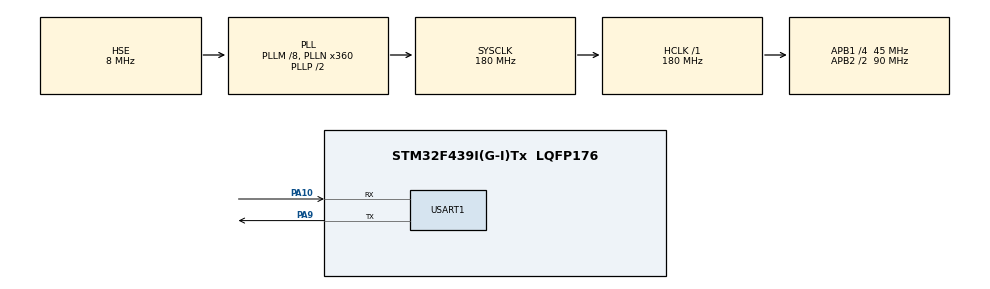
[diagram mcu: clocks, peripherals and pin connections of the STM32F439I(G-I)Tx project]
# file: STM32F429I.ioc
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Dma.Request0=USART1_TX
Dma.USART1_TX.0.Channel=DMA_CHANNEL_4
Dma.USART1_TX.0.Direction=DMA_MEMORY_TO_PERIPH
Dma.USART1_TX.0.FIFOMode=DMA_FIFOMODE_DISABLE
Dma.USART1_TX.0.Instance=DMA2_Stream7
Dma.USART1_TX.0.MemBurst=DMA_MBURST_SINGLE
Dma.USART1_TX.0.MemDataAlignment=DMA_MDATAALIGN_BYTE
Dma.USART1_TX.0.MemInc=DMA_MINC_ENABLE
Dma.USART1_TX.0.Mode=DMA_NORMAL
Dma.USART1_TX.0.PeriphBurst=DMA_PBURST_SINGLE
Dma.USART1_TX.0.PeriphDataAlignment=DMA_PDATAALIGN_BYTE
Dma.USART1_TX.0.PeriphInc=DMA_PINC_DISABLE
Dma.USART1_TX.0.Priority=DMA_PRIORITY_HIGH
Mcu.Family=STM32F4
Mcu.Name=STM32F439I(G-I)Tx
Mcu.Package=LQFP176
NVIC.DMA2_Stream7_IRQn=true\:0\:1\:true
NVIC.PriorityGroup=NVIC_PRIORITYGROUP_3
NVIC.USART1_IRQn=true\:0\:0\:false
PA10.Mode=Asynchronous
PA10.Signal=USART1_RX
PA9.Mode=Asynchronous
PA9.Signal=USART1_TX
PH0/OSC_IN.Mode=HSE-External-Oscillator
PH0/OSC_IN.Signal=RCC_OSC_IN
PH1/OSC_OUT.Mode=HSE-External-Oscillator
PH1/OSC_OUT.Signal=RCC_OSC_OUT
ProjectManager.TargetToolchain=MDK-ARM V5
RCC.48MHZClocksFreq_Value=90000000
RCC.AHBFreq_Value=180000000
RCC.APB1CLKDivider=RCC_HCLK_DIV4
RCC.APB1Freq_Value=45000000
RCC.APB1TimFreq_Value=90000000
RCC.APB2CLKDivider=RCC_HCLK_DIV2
RCC.APB2Freq_Value=90000000
RCC.APB2TimFreq_Value=180000000
RCC.CortexFreq_Value=180000000
RCC.HCLKFreq_Value=180000000
RCC.HSE_VALUE=8000000
RCC.HSI_VALUE=16000000
RCC.LSE_VALUE=32768
RCC.PLLM=8
RCC.PLLN=360
RCC.PLLSourceVirtual=RCC_PLLSOURCE_HSE
RCC.SYSCLKFreq_VALUE=180000000
RCC.SYSCLKSource=RCC_SYSCLKSOURCE_PLLCLK
RCC.VCOOutputFreq_Value=360000000
board=STM32F429I

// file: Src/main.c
/**
  ******************************************************************************
  * File Name          : main.c
  * Description        : Main program body
  ******************************************************************************
  *
  * COPYRIGHT(c) 2015 STMicroelectronics
  *
  * Redistribution and use in source and binary forms, with or without modification,
  * are permitted provided that the following conditions are met:
  *   1. Redistributions of source code must retain the above copyright notice,
  *      this list of conditions and the following disclaimer.
  *   2. Redistributions in binary form must reproduce the above copyright notice,
  *      this list of conditions and the following disclaimer in the documentation
  *      and/or other materials provided with the distribution.
  *   3. Neither the name of STMicroelectronics nor the names of its contributors
  *      may be used to endorse or promote products derived from this software
  *      without specific prior written permission.
  *
  * THIS SOFTWARE IS PROVIDED BY THE COPYRIGHT HOLDERS AND CONTRIBUTORS "AS IS"
  * AND ANY EXPRESS OR IMPLIED WARRANTIES, INCLUDING, BUT NOT LIMITED TO, THE
  * IMPLIED WARRANTIES OF MERCHANTABILITY AND FITNESS FOR A PARTICULAR PURPOSE ARE
  * DISCLAIMED. IN NO EVENT SHALL THE COPYRIGHT HOLDER OR CONTRIBUTORS BE LIABLE
  * FOR ANY DIRECT, INDIRECT, INCIDENTAL, SPECIAL, EXEMPLARY, OR CONSEQUENTIAL
  * DAMAGES (INCLUDING, BUT NOT LIMITED TO, PROCUREMENT OF SUBSTITUTE GOODS OR
  * SERVICES; LOSS OF USE, DATA, OR PROFITS; OR BUSINESS INTERRUPTION) HOWEVER
  * CAUSED AND ON ANY THEORY OF LIABILITY, WHETHER IN CONTRACT, STRICT LIABILITY,
  * OR TORT (INCLUDING NEGLIGENCE OR OTHERWISE) ARISING IN ANY WAY OUT OF THE USE
  * OF THIS SOFTWARE, EVEN IF ADVISED OF THE POSSIBILITY OF SUCH DAMAGE.
  *
  ******************************************************************************
  */
#include "stm32f4xx_hal.h"
#include "dma.h"
#include "usart.h"
#include "gpio.h"

/* USER CODE BEGIN PV */
/* Private variables ---------------------------------------------------------*/
uint8_t aTxMessage[] = "\r\n**** UART-Hyperterminal communication based on DMA ***\r\n    WaveShare Open4X9I-C Board \r\n";
/* USER CODE END PV */

void SystemClock_Config(void);

/* USER CODE BEGIN PFP */
/* Private function prototypes -----------------------------------------------*/

/* USER CODE END PFP */

int main(void)
{

  /* MCU Configuration----------------------------------------------------------*/

  /* Reset of all peripherals, Initializes the Flash interface and the Systick. */
  HAL_Init();

  /* Configure the system clock */
  SystemClock_Config();

  /* Initialize all configured peripherals */
  MX_GPIO_Init();
  MX_DMA_Init();
  MX_USART1_UART_Init();

  /* Infinite loop */
  while (1)
  {

  /* USER CODE BEGIN 3 */
	if (HAL_UART_Transmit_DMA(&huart1, (uint8_t *)aTxMessage, sizeof(aTxMessage)) != HAL_OK)
  {
    /* Transfer error in reception process */
    while(1);
  }
	HAL_Delay(1000);
  }
  /* USER CODE END 3 */

}

/** System Clock Configuration
*/
void SystemClock_Config(void)
{

  RCC_OscInitTypeDef RCC_OscInitStruct;
  RCC_ClkInitTypeDef RCC_ClkInitStruct;

  __PWR_CLK_ENABLE();

  __HAL_PWR_VOLTAGESCALING_CONFIG(PWR_REGULATOR_VOLTAGE_SCALE1);

  RCC_OscInitStruct.OscillatorType = RCC_OSCILLATORTYPE_HSE;
  RCC_OscInitStruct.HSEState = RCC_HSE_ON;
  RCC_OscInitStruct.PLL.PLLState = RCC_PLL_ON;
  RCC_OscInitStruct.PLL.PLLSource = RCC_PLLSOURCE_HSE;
  RCC_OscInitStruct.PLL.PLLM = 8;
  RCC_OscInitStruct.PLL.PLLN = 360;
  RCC_OscInitStruct.PLL.PLLP = RCC_PLLP_DIV2;
  RCC_OscInitStruct.PLL.PLLQ = 4;
  HAL_RCC_OscConfig(&RCC_OscInitStruct);

  HAL_PWREx_ActivateOverDrive();

  RCC_ClkInitStruct.ClockType = RCC_CLOCKTYPE_SYSCLK|RCC_CLOCKTYPE_PCLK1
                              |RCC_CLOCKTYPE_PCLK2;
  RCC_ClkInitStruct.SYSCLKSource = RCC_SYSCLKSOURCE_PLLCLK;
  RCC_ClkInitStruct.AHBCLKDivider = RCC_SYSCLK_DIV1;
  RCC_ClkInitStruct.APB1CLKDivider = RCC_HCLK_DIV4;
  RCC_ClkInitStruct.APB2CLKDivider = RCC_HCLK_DIV2;
  HAL_RCC_ClockConfig(&RCC_ClkInitStruct, FLASH_LATENCY_5);

  HAL_SYSTICK_Config(HAL_RCC_GetHCLKFreq()/1000);

  HAL_SYSTICK_CLKSourceConfig(SYSTICK_CLKSOURCE_HCLK);

  /* SysTick_IRQn interrupt configuration */
  HAL_NVIC_SetPriority(SysTick_IRQn, 0, 0);
}

/************************ (C) COPYRIGHT STMicroelectronics *****END OF FILE****/
